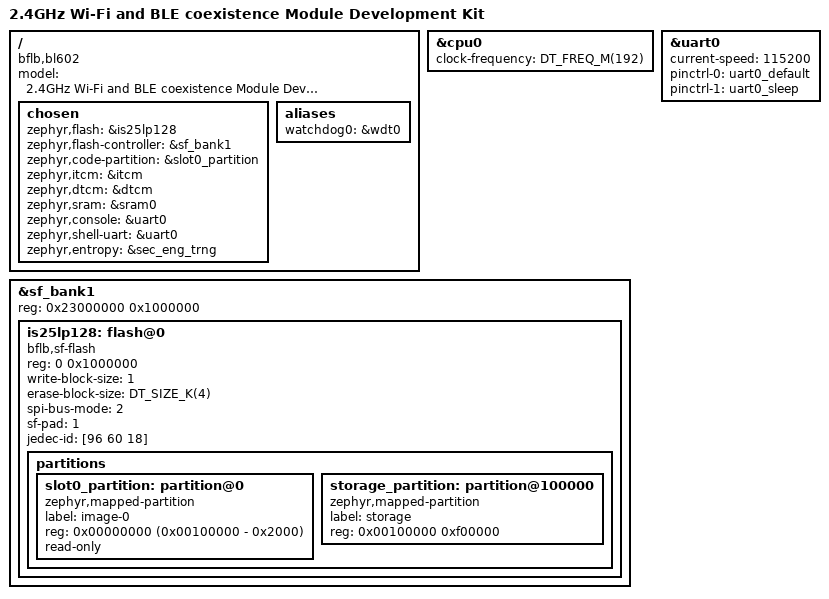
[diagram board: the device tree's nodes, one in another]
/*
 * Copyright (c) 2021-2025 ATL Electronics
 * SPDX-License-Identifier: Apache-2.0
 */

/dts-v1/;

#include <bflb/bl60x.dtsi>
#include "dt_bl10_devkit-pinctrl.dtsi"

/ {
	model = "2.4GHz Wi-Fi and BLE coexistence Module Development Kit";
	compatible = "bflb,bl602";

	chosen {
		zephyr,flash = &is25lp128;
		zephyr,flash-controller = &sf_bank1;
		zephyr,code-partition = &slot0_partition;
		zephyr,itcm = &itcm;
		zephyr,dtcm = &dtcm;
		zephyr,sram = &sram0;
		zephyr,console = &uart0;
		zephyr,shell-uart = &uart0;
		zephyr,entropy = &sec_eng_trng;
	};

	aliases {
		watchdog0 = &wdt0;
	};
};

&cpu0 {
	clock-frequency = <DT_FREQ_M(192)>;
};

&sf_bank1 {
	reg = <0x23000000 0x1000000>;
	ranges = <0x0 0x23000000 0x1000000>;

	is25lp128: flash@0 {
		compatible = "bflb,sf-flash", "soc-nv-flash";
		reg = <0 0x1000000>;
		write-block-size = <1>;
		erase-block-size = <DT_SIZE_K(4)>;

		spi-bus-mode = <2>;
		sf-pad = <1>;
		jedec-id = [96 60 18];

		partitions {
			#address-cells = <1>;
			#size-cells = <1>;

			slot0_partition: partition@0 {
				compatible = "zephyr,mapped-partition";
				label = "image-0";
				reg = <0x00000000 (0x00100000 - 0x2000)>;
				read-only;
			};

			storage_partition: partition@100000 {
				compatible = "zephyr,mapped-partition";
				label = "storage";
				reg = <0x00100000 0xf00000>;
			};
		};
	};
};

&uart0 {
	status = "okay";
	current-speed = <115200>;

	pinctrl-0 = <&uart0_default>;
	pinctrl-1 = <&uart0_sleep>;
	pinctrl-names = "default", "sleep";
};
